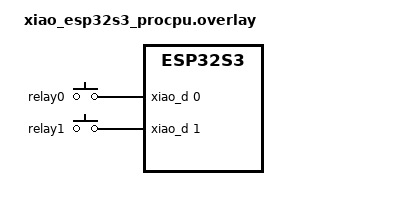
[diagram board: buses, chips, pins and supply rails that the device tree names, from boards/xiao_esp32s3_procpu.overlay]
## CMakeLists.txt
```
# SPDX-License-Identifier: Apache-2.0

cmake_minimum_required(VERSION 3.20.0)

set(SHIELD seeed_b2b_sx1262)

# It seems appropriate to put this *after* the Zephyr package but it only
# affects the build if we put it here. I'm surely doing something wrong.
set_property(GLOBAL APPEND PROPERTY extra_post_build_commands
        COMMAND ${PYTHON_EXECUTABLE} "$ENV{ZEPHYR_BASE}/../common/scripts/incr_build.py"
        ARGS ${CMAKE_CURRENT_SOURCE_DIR}/VERSION
)

find_package(Zephyr REQUIRED HINTS $ENV{ZEPHYR_BASE})
project(lora_garage)

add_subdirectory(../common lora-common)

FILE(GLOB app_sources src/*.c)
target_sources(app PRIVATE ${app_sources} ${common_sources} ${common_board_sources})

target_sources(app PRIVATE
        ${ZEPHYR_HAL_ESPRESSIF_MODULE_DIR}/components/hal/hmac_hal.c
        ${ZEPHYR_HAL_ESPRESSIF_MODULE_DIR}/components/hal/aes_hal.c
        ${ZEPHYR_HAL_ESPRESSIF_MODULE_DIR}/components/efuse/src/efuse_controller/keys/with_key_purposes/esp_efuse_api_key.c
        ${ZEPHYR_HAL_ESPRESSIF_MODULE_DIR}/components/efuse/src/esp_efuse_api.c
        ${ZEPHYR_HAL_ESPRESSIF_MODULE_DIR}/components/efuse/src/esp_efuse_utility.c
        ${ZEPHYR_HAL_ESPRESSIF_MODULE_DIR}/components/efuse/${CONFIG_SOC_SERIES}/esp_efuse_utility.c
        ${ZEPHYR_HAL_ESPRESSIF_MODULE_DIR}/components/efuse/${CONFIG_SOC_SERIES}/esp_efuse_table.c
)
```

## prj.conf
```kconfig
# General Zephyr settings
CONFIG_MAIN_STACK_SIZE=2048
CONFIG_SYSTEM_WORKQUEUE_STACK_SIZE=4096
CONFIG_STACK_SENTINEL=y
CONFIG_THREAD_NAME=y
CONFIG_LOG=y
CONFIG_LOG_THREAD_ID_PREFIX=y
CONFIG_LOG_PROCESS_THREAD_STACK_SIZE=4096
CONFIG_LOG_BUFFER_SIZE=8192
CONFIG_LOG_PROCESS_THREAD_SLEEP_MS=200
CONFIG_LOG_SPEED=y

# LoRa PHY
CONFIG_LORA=y
#CONFIG_LORA_LOG_LEVEL_DBG=y

# NVS required to store LoRaWAN DevNonce
CONFIG_NVS=y
#CONFIG_NVS_LOG_LEVEL_DBG=y
CONFIG_SETTINGS=y
CONFIG_SETTINGS_DYNAMIC_HANDLERS=n
#CONFIG_SETTINGS_LOG_LEVEL_DBG=y
# The NVS settings implementation is braindead without this
CONFIG_SETTINGS_NVS_NAME_CACHE=y
# Sector size is 4kB
CONFIG_SETTINGS_NVS_SECTOR_SIZE_MULT=1
CONFIG_SETTINGS_NVS_SECTOR_COUNT=8

# Random number generator required for several LoRaWAN services
CONFIG_ENTROPY_GENERATOR=y

# LoRaWAN application layer
CONFIG_LORAWAN=y
CONFIG_LORAMAC_REGION_US915=y
CONFIG_LORAWAN_NVM_SETTINGS=y
#CONFIG_LORAWAN_LOG_LEVEL_DBG=y

# LoRaWAN services required for FUOTA
CONFIG_LORAWAN_SERVICES=y
CONFIG_LORAWAN_SERVICES_LOG_LEVEL_DBG=y
CONFIG_LORAWAN_SERVICES_MAX_UPLINK_SIZE=36
CONFIG_LORAWAN_APP_CLOCK_SYNC=y
CONFIG_LORAWAN_REMOTE_MULTICAST=y
CONFIG_LORAWAN_FRAG_TRANSPORT=y

# use fixed frag size (min and max 232 bytes) to avoid RAM overflow
CONFIG_LORAWAN_FRAG_TRANSPORT_MIN_FRAG_SIZE=232
# alternatively, the redundancy could be reduced
CONFIG_LORAWAN_FRAG_TRANSPORT_MAX_REDUNDANCY=4
CONFIG_LORAWAN_FRAG_TRANSPORT_DECODER_LOWMEM=y

# auto-reboot
CONFIG_REBOOT=y

# Use Semtech soft secure element implementation until we port PSA
CONFIG_HAS_SEMTECH_SOFT_SE=y

# Flash driver to store firmware image
CONFIG_FLASH=y
CONFIG_FLASH_MAP=y
CONFIG_FLASH_PAGE_LAYOUT=y
CONFIG_STREAM_FLASH=y
CONFIG_IMG_MANAGER=y

# hwinfo for unique ID
CONFIG_HWINFO=y

# ESP32S3 appears to use a real serial port for CDC/ACM
CONFIG_SERIAL=y
# and it needs to be efficient
CONFIG_UART_INTERRUPT_DRIVEN=y
CONFIG_CONSOLE=y
CONFIG_UART_CONSOLE=y

# Scheduling functionality
CONFIG_RTC=y
# App configuration
CONFIG_LORAWAN_PORT_RELAY_BASE=0x81
CONFIG_ENTRANCE_HAS_AUTO_CLOSE=n

# Power management
#CONFIG_PM=y
#CONFIG_PM_DEVICE=y

# Debugging
CONFIG_DEBUG=y
CONFIG_DEBUG_THREAD_INFO=y
CONFIG_OUTPUT_SYMBOLS=y
CONFIG_THREAD_ANALYZER=y
```

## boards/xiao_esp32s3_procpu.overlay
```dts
#include <dt-bindings/pinctrl/esp32s3-pinctrl.h>

/ {
	aliases {
		relay0 = &relay_btn0;
		relay1 = &relay_btn1;
	};

	buttons {
		compatible = "gpio-keys";

		relay_btn0: button_0 {
			gpios = <&xiao_d 0 (GPIO_ACTIVE_HIGH | GPIO_PUSH_PULL)>;
			label = "relay0";
		};

		relay_btn1: button_1 {
			gpios = <&xiao_d 1 (GPIO_ACTIVE_HIGH | GPIO_PUSH_PULL)>;
			label = "relay1";
		};
	};
};
```

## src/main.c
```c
/*
 * LoRaWAN FUOTA sample application
 *
 * Copyright (c) 2022-2024 Libre Solar Technologies GmbH
 * Copyright (c) 2022-2024 tado GmbH
 *
 * SPDX-License-Identifier: Apache-2.0
 */

#include <zephyr/device.h>
#include <zephyr/kernel.h>
#include <zephyr/logging/log.h>
#include <zephyr/drivers/lora.h>
#include <zephyr/lorawan/lorawan.h>

#include "fuota.h"
#include "relay.h"

LOG_MODULE_REGISTER(main, CONFIG_LORAWAN_SERVICES_LOG_LEVEL);

static const struct device *lora_dev = DEVICE_DT_GET(DT_ALIAS(lora0));

static uint8_t battery_cb(void) {
	return 0; /* A value of 0 indicates external power */
}

int lora_init(void) {
	if (!device_is_ready(lora_dev)) {
		LOG_ERR("%s: device not ready.", lora_dev->name);
		return -ENODEV;
	}

	lorawan_register_battery_level_callback(battery_cb);

        return 0;
}

uint8_t remote_msg[8] = {0};

int main(void)
{
	int ret;

	ret = lora_init();
	if (ret != 0) {
		LOG_ERR("Failed to initialize LoRa");
		goto err;
	}

	fuota_run();

	/* Wait for datarate change*/
	wait_for_datarate(LORAWAN_DR_3);
	report_version();

	lorawan_relay_run();

	while (1) {
		k_sleep(K_MINUTES(5));
	}

err:
	return 0;
}
```
